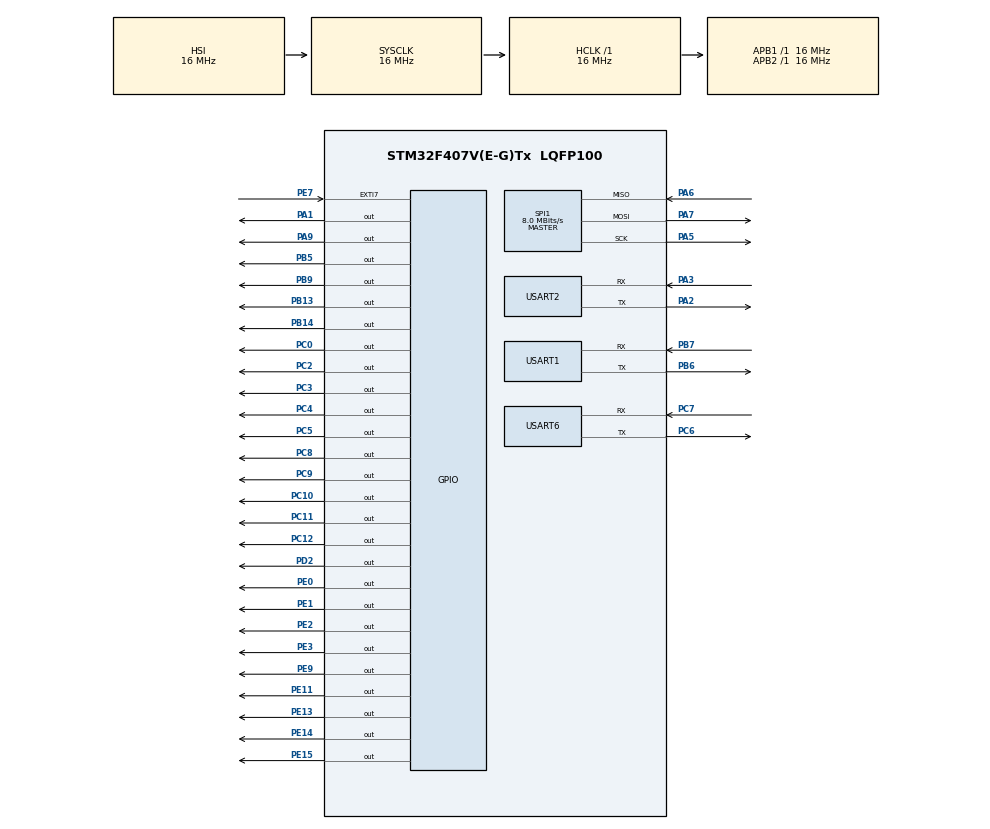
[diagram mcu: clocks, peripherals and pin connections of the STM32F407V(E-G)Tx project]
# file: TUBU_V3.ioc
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Mcu.Family=STM32F4
Mcu.Name=STM32F407V(E-G)Tx
Mcu.Package=LQFP100
NVIC.PriorityGroup=NVIC_PRIORITYGROUP_4
PA0-WKUP.Mode=SYS_WakeUp0
PA0-WKUP.Signal=SYS_WKUP
PA1.Signal=GPIO_Output
PA13.Mode=Serial_Wire
PA13.Signal=SYS_JTMS-SWDIO
PA14.Mode=Serial_Wire
PA14.Signal=SYS_JTCK-SWCLK
PA2.Mode=Asynchronous
PA2.Signal=USART2_TX
PA3.Mode=Asynchronous
PA3.Signal=USART2_RX
PA5.Mode=Full_Duplex_Master
PA5.Signal=SPI1_SCK
PA6.Mode=Full_Duplex_Master
PA6.Signal=SPI1_MISO
PA7.Mode=Full_Duplex_Master
PA7.Signal=SPI1_MOSI
PA9.Signal=GPIO_Output
PB13.Signal=GPIO_Output
PB14.Signal=GPIO_Output
PB5.Signal=GPIO_Output
PB6.Mode=Asynchronous
PB6.Signal=USART1_TX
PB7.Mode=Asynchronous
PB7.Signal=USART1_RX
PB9.Signal=GPIO_Output
PC0.Signal=GPIO_Output
PC10.Signal=GPIO_Output
PC11.Signal=GPIO_Output
PC12.Signal=GPIO_Output
PC14-OSC32_IN.Mode=LSE-External-Oscillator
PC14-OSC32_IN.Signal=RCC_OSC32_IN
PC15-OSC32_OUT.Mode=LSE-External-Oscillator
PC15-OSC32_OUT.Signal=RCC_OSC32_OUT
PC2.Signal=GPIO_Output
PC3.Signal=GPIO_Output
PC4.Signal=GPIO_Output
PC5.Signal=GPIO_Output
PC6.Mode=Asynchronous
PC6.Signal=USART6_TX
PC7.Mode=Asynchronous
PC7.Signal=USART6_RX
PC8.Signal=GPIO_Output
PC9.Signal=GPIO_Output
PD2.Signal=GPIO_Output
PE0.Signal=GPIO_Output
PE1.Signal=GPIO_Output
PE11.Signal=GPIO_Output
PE13.Signal=GPIO_Output
PE14.Signal=GPIO_Output
PE15.Signal=GPIO_Output
PE2.Signal=GPIO_Output
PE3.Signal=GPIO_Output
PE7.Signal=GPXTI7
PE9.Signal=GPIO_Output
PH0-OSC_IN.Mode=HSE-External-Oscillator
PH0-OSC_IN.Signal=RCC_OSC_IN
PH1-OSC_OUT.Mode=HSE-External-Oscillator
PH1-OSC_OUT.Signal=RCC_OSC_OUT
ProjectManager.HeapSize=0x200
ProjectManager.StackSize=0x400
ProjectManager.TargetToolchain=STM32CubeIDE
RCC.AHBFreq_Value=16000000
RCC.APB1Freq_Value=16000000
RCC.APB2Freq_Value=16000000
RCC.CortexFreq_Value=16000000
RCC.HSE_VALUE=25000000
RCC.HSI_VALUE=16000000
RCC.SYSCLKFreq_VALUE=16000000
RCC.VCOOutputFreq_Value=192000000
SPI1.CalculateBaudRate=8.0 MBits/s
SPI1.Direction=SPI_DIRECTION_2LINES
SPI1.Mode=SPI_MODE_MASTER
SPI1.VirtualType=VM_MASTER
USART1.VirtualMode=VM_ASYNC
USART2.VirtualMode=VM_ASYNC
USART6.VirtualMode=VM_ASYNC
VP_CRC_VS_CRC.Mode=CRC_Activate
VP_FATFS_VS_Generic.Mode=User_defined
board=custom

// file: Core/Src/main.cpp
/* USER CODE BEGIN Header */
/**
  ******************************************************************************
  * @file           : main.c
  * @brief          : Main program body
  ******************************************************************************
  * @attention
  *
  * Copyright (c) 2023 STMicroelectronics.
  * All rights reserved.
  *
  * This software is licensed under terms that can be found in the LICENSE file
  * in the root directory of this software component.
  * If no LICENSE file comes with this software, it is provided AS-IS.
  *
  ******************************************************************************
  */
/* USER CODE END Header */
#include "main.h"
#include "fatfs.h"

/* USER CODE BEGIN Includes */
#include "sim.h"
#include "ducati.h"
/* USER CODE END Includes */

CRC_HandleTypeDef hcrc;

SPI_HandleTypeDef hspi1;

UART_HandleTypeDef huart1;
UART_HandleTypeDef huart2;
UART_HandleTypeDef huart6;

void SystemClock_Config(void);
static void MX_GPIO_Init(void);
static void MX_SPI1_Init(void);
static void MX_USART1_UART_Init(void);
static void MX_USART2_UART_Init(void);
static void MX_USART6_UART_Init(void);
static void MX_CRC_Init(void);

int main(void)
{

  /* MCU Configuration--------------------------------------------------------*/

  /* Reset of all peripherals, Initializes the Flash interface and the Systick. */
  HAL_Init();

  /* Configure the system clock */
  SystemClock_Config();

  /* Initialize all configured peripherals */
  MX_GPIO_Init();
  MX_SPI1_Init();
  MX_USART1_UART_Init();
  MX_USART2_UART_Init();
  MX_USART6_UART_Init();
  MX_FATFS_Init();
  MX_CRC_Init();

  /* Infinite loop */
  while (1)
  {

  }
}

void SystemClock_Config(void)
{
  RCC_OscInitTypeDef RCC_OscInitStruct = {0};
  RCC_ClkInitTypeDef RCC_ClkInitStruct = {0};

  /** Configure the main internal regulator output voltage
  */
  __HAL_RCC_PWR_CLK_ENABLE();
  __HAL_PWR_VOLTAGESCALING_CONFIG(PWR_REGULATOR_VOLTAGE_SCALE1);

  /** Initializes the RCC Oscillators according to the specified parameters
  * in the RCC_OscInitTypeDef structure.
  */
  RCC_OscInitStruct.OscillatorType = RCC_OSCILLATORTYPE_HSI;
  RCC_OscInitStruct.HSIState = RCC_HSI_ON;
  RCC_OscInitStruct.HSICalibrationValue = RCC_HSICALIBRATION_DEFAULT;
  RCC_OscInitStruct.PLL.PLLState = RCC_PLL_NONE;
  if (HAL_RCC_OscConfig(&RCC_OscInitStruct) != HAL_OK)
  {
    Error_Handler();
  }

  /** Initializes the CPU, AHB and APB buses clocks
  */
  RCC_ClkInitStruct.ClockType = RCC_CLOCKTYPE_HCLK|RCC_CLOCKTYPE_SYSCLK
                              |RCC_CLOCKTYPE_PCLK1|RCC_CLOCKTYPE_PCLK2;
  RCC_ClkInitStruct.SYSCLKSource = RCC_SYSCLKSOURCE_HSI;
  RCC_ClkInitStruct.AHBCLKDivider = RCC_SYSCLK_DIV1;
  RCC_ClkInitStruct.APB1CLKDivider = RCC_HCLK_DIV1;
  RCC_ClkInitStruct.APB2CLKDivider = RCC_HCLK_DIV1;

  if (HAL_RCC_ClockConfig(&RCC_ClkInitStruct, FLASH_LATENCY_0) != HAL_OK)
  {
    Error_Handler();
  }
}

static void MX_CRC_Init(void)
{

  hcrc.Instance = CRC;
  if (HAL_CRC_Init(&hcrc) != HAL_OK)
  {
    Error_Handler();
  }

}

static void MX_SPI1_Init(void)
{

  /* SPI1 parameter configuration*/
  hspi1.Instance = SPI1;
  hspi1.Init.Mode = SPI_MODE_MASTER;
  hspi1.Init.Direction = SPI_DIRECTION_2LINES;
  hspi1.Init.DataSize = SPI_DATASIZE_8BIT;
  hspi1.Init.CLKPolarity = SPI_POLARITY_LOW;
  hspi1.Init.CLKPhase = SPI_PHASE_1EDGE;
  hspi1.Init.NSS = SPI_NSS_SOFT;
  hspi1.Init.BaudRatePrescaler = SPI_BAUDRATEPRESCALER_2;
  hspi1.Init.FirstBit = SPI_FIRSTBIT_MSB;
  hspi1.Init.TIMode = SPI_TIMODE_DISABLE;
  hspi1.Init.CRCCalculation = SPI_CRCCALCULATION_DISABLE;
  hspi1.Init.CRCPolynomial = 10;
  if (HAL_SPI_Init(&hspi1) != HAL_OK)
  {
    Error_Handler();
  }

}

static void MX_USART1_UART_Init(void)
{

  huart1.Instance = USART1;
  huart1.Init.BaudRate = 115200;
  huart1.Init.WordLength = UART_WORDLENGTH_8B;
  huart1.Init.StopBits = UART_STOPBITS_1;
  huart1.Init.Parity = UART_PARITY_NONE;
  huart1.Init.Mode = UART_MODE_TX_RX;
  huart1.Init.HwFlowCtl = UART_HWCONTROL_NONE;
  huart1.Init.OverSampling = UART_OVERSAMPLING_16;
  if (HAL_UART_Init(&huart1) != HAL_OK)
  {
    Error_Handler();
  }

}

static void MX_USART2_UART_Init(void)
{

  huart2.Instance = USART2;
  huart2.Init.BaudRate = 115200;
  huart2.Init.WordLength = UART_WORDLENGTH_8B;
  huart2.Init.StopBits = UART_STOPBITS_1;
  huart2.Init.Parity = UART_PARITY_NONE;
  huart2.Init.Mode = UART_MODE_TX_RX;
  huart2.Init.HwFlowCtl = UART_HWCONTROL_NONE;
  huart2.Init.OverSampling = UART_OVERSAMPLING_16;
  if (HAL_UART_Init(&huart2) != HAL_OK)
  {
    Error_Handler();
  }

}

static void MX_USART6_UART_Init(void)
{

  huart6.Instance = USART6;
  huart6.Init.BaudRate = 115200;
  huart6.Init.WordLength = UART_WORDLENGTH_8B;
  huart6.Init.StopBits = UART_STOPBITS_1;
  huart6.Init.Parity = UART_PARITY_NONE;
  huart6.Init.Mode = UART_MODE_TX_RX;
  huart6.Init.HwFlowCtl = UART_HWCONTROL_NONE;
  huart6.Init.OverSampling = UART_OVERSAMPLING_16;
  if (HAL_UART_Init(&huart6) != HAL_OK)
  {
    Error_Handler();
  }

}

static void MX_GPIO_Init(void)
{
  GPIO_InitTypeDef GPIO_InitStruct = {0};

  /* GPIO Ports Clock Enable */
  __HAL_RCC_GPIOE_CLK_ENABLE();
  __HAL_RCC_GPIOC_CLK_ENABLE();
  __HAL_RCC_GPIOH_CLK_ENABLE();
  __HAL_RCC_GPIOA_CLK_ENABLE();
  __HAL_RCC_GPIOB_CLK_ENABLE();
  __HAL_RCC_GPIOD_CLK_ENABLE();

  /*Configure GPIO pin Output Level */
  HAL_GPIO_WritePin(GPIOE, GPIO_PIN_2|GPIO_PIN_3|GPIO_PIN_9|GPIO_PIN_11
                          |GPIO_PIN_13|GPIO_PIN_14|GPIO_PIN_15|GPIO_PIN_0
                          |GPIO_PIN_1, GPIO_PIN_RESET);

  /*Configure GPIO pin Output Level */
  HAL_GPIO_WritePin(GPIOC, GPIO_PIN_0|GPIO_PIN_2|GPIO_PIN_3|GPIO_PIN_4
                          |GPIO_PIN_5|GPIO_PIN_8|GPIO_PIN_9|GPIO_PIN_10
                          |GPIO_PIN_11|GPIO_PIN_12, GPIO_PIN_RESET);

  /*Configure GPIO pin Output Level */
  HAL_GPIO_WritePin(GPIOA, GPIO_PIN_1|GPIO_PIN_9, GPIO_PIN_RESET);

  /*Configure GPIO pin Output Level */
  HAL_GPIO_WritePin(GPIOB, GPIO_PIN_13|GPIO_PIN_14|GPIO_PIN_5|GPIO_PIN_9, GPIO_PIN_RESET);

  /*Configure GPIO pin Output Level */
  HAL_GPIO_WritePin(GPIOD, GPIO_PIN_2, GPIO_PIN_RESET);

  /*Configure GPIO pins : PE2 PE3 PE9 PE11
                           PE13 PE14 PE15 PE0
                           PE1 */
  GPIO_InitStruct.Pin = GPIO_PIN_2|GPIO_PIN_3|GPIO_PIN_9|GPIO_PIN_11
                          |GPIO_PIN_13|GPIO_PIN_14|GPIO_PIN_15|GPIO_PIN_0
                          |GPIO_PIN_1;
  GPIO_InitStruct.Mode = GPIO_MODE_OUTPUT_PP;
  GPIO_InitStruct.Pull = GPIO_NOPULL;
  GPIO_InitStruct.Speed = GPIO_SPEED_FREQ_LOW;
  HAL_GPIO_Init(GPIOE, &GPIO_InitStruct);

  /*Configure GPIO pins : PC0 PC2 PC3 PC4
                           PC5 PC8 PC9 PC10
                           PC11 PC12 */
  GPIO_InitStruct.Pin = GPIO_PIN_0|GPIO_PIN_2|GPIO_PIN_3|GPIO_PIN_4
                          |GPIO_PIN_5|GPIO_PIN_8|GPIO_PIN_9|GPIO_PIN_10
                          |GPIO_PIN_11|GPIO_PIN_12;
  GPIO_InitStruct.Mode = GPIO_MODE_OUTPUT_PP;
  GPIO_InitStruct.Pull = GPIO_NOPULL;
  GPIO_InitStruct.Speed = GPIO_SPEED_FREQ_LOW;
  HAL_GPIO_Init(GPIOC, &GPIO_InitStruct);

  /*Configure GPIO pins : PA1 PA9 */
  GPIO_InitStruct.Pin = GPIO_PIN_1|GPIO_PIN_9;
  GPIO_InitStruct.Mode = GPIO_MODE_OUTPUT_PP;
  GPIO_InitStruct.Pull = GPIO_NOPULL;
  GPIO_InitStruct.Speed = GPIO_SPEED_FREQ_LOW;
  HAL_GPIO_Init(GPIOA, &GPIO_InitStruct);

  /*Configure GPIO pin : PE7 */
  GPIO_InitStruct.Pin = GPIO_PIN_7;
  GPIO_InitStruct.Mode = GPIO_MODE_IT_RISING;
  GPIO_InitStruct.Pull = GPIO_NOPULL;
  HAL_GPIO_Init(GPIOE, &GPIO_InitStruct);

  /*Configure GPIO pins : PB13 PB14 PB5 PB9 */
  GPIO_InitStruct.Pin = GPIO_PIN_13|GPIO_PIN_14|GPIO_PIN_5|GPIO_PIN_9;
  GPIO_InitStruct.Mode = GPIO_MODE_OUTPUT_PP;
  GPIO_InitStruct.Pull = GPIO_NOPULL;
  GPIO_InitStruct.Speed = GPIO_SPEED_FREQ_LOW;
  HAL_GPIO_Init(GPIOB, &GPIO_InitStruct);

  /*Configure GPIO pin : PD2 */
  GPIO_InitStruct.Pin = GPIO_PIN_2;
  GPIO_InitStruct.Mode = GPIO_MODE_OUTPUT_PP;
  GPIO_InitStruct.Pull = GPIO_NOPULL;
  GPIO_InitStruct.Speed = GPIO_SPEED_FREQ_LOW;
  HAL_GPIO_Init(GPIOD, &GPIO_InitStruct);

}

void Error_Handler(void)
{
  __disable_irq();
  while (1)
  {
  }
}
